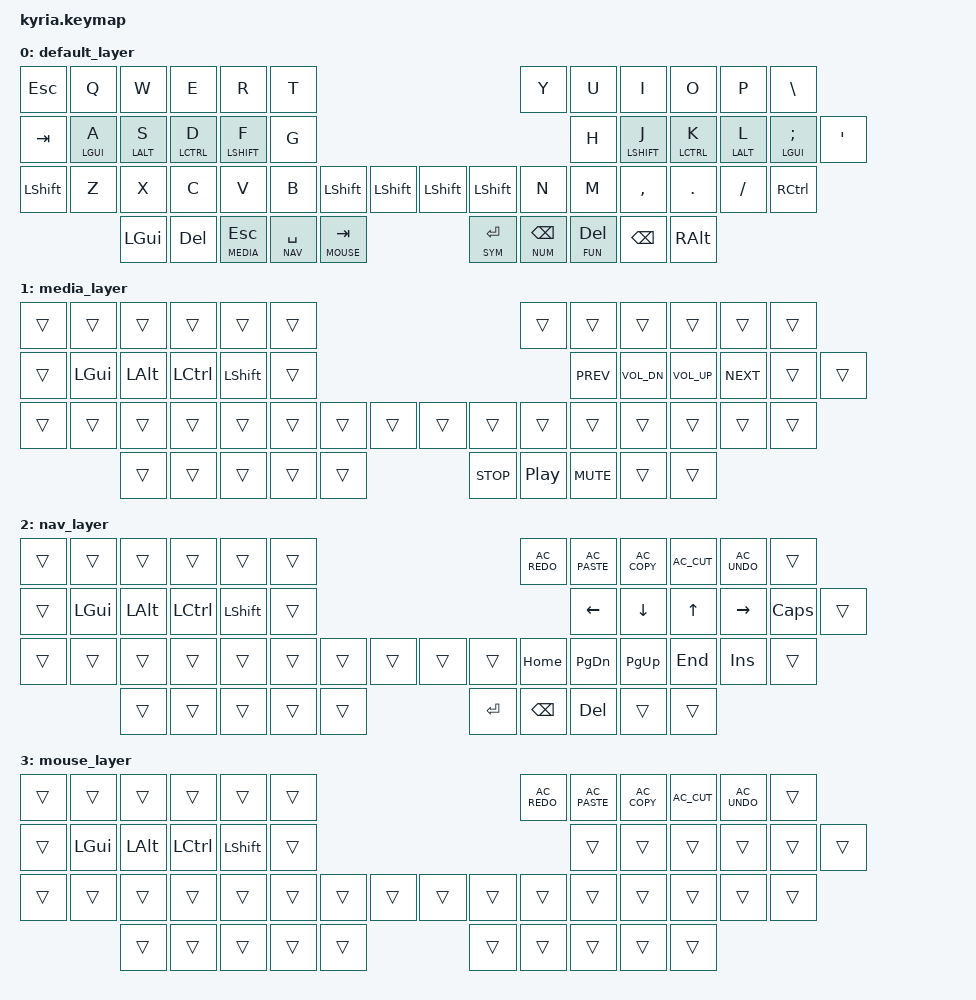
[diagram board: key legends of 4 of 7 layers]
/*
 * Copyright (c) 2020 The ZMK Contributors
 *
 * SPDX-License-Identifier: MIT
 *
 * This is an implementation of Miryoku for Kyria, with the following minor modifications:
 *   - Default is based on the default Kyria keymap.
 *   - This uses the QWERTY layout:
 *       MIRYOKU_ALPHAS=QWERTY
 *   - I am used to vi-style navigation:
 *       MIRYOKU_NAV=VI
 */

#include <behaviors.dtsi>
#include <dt-bindings/zmk/keys.h>
#include <dt-bindings/zmk/bt.h>

#define DEFAULT 0
#define MEDIA 1
#define NAV 2
#define MOUSE 3
#define SYM 4
#define NUM 5
#define FUN 6
#define BUTTON 7

/ {
	keymap {
		compatible = "zmk,keymap";

		default_layer {
// ---------------------------------------------------------------------------------------------------------------------------------
// |  ESC  |  Q  |  W  |  E   |  R   |  T   |                                          |  Y   |  U    |  I    |  O   |   P   |   \  |
// |  TAB  |  A  |  S  |  D   |  F   |  G   |                                          |  H   |  J    |  K    |  L   |   ;   |   '  |
// | SHIFT |  Z  |  X  |  C   |  V   |  B   | L SHIFT | L SHIFT |  | L SHIFT | L SHIFT |  N   |  M    |  ,    |  .   |   /   | CTRL |
//                     | GUI  | DEL  | RET  |  SPACE  |   ESC   |  |   RET   |  SPACE  | TAB  | BSPC  | R-ALT |
			bindings = <
	&kp ESC   &kp Q     &kp W     &kp E     &kp R     &kp T                                                &kp Y &kp U      &kp I         &kp O       &kp P        &kp BSLH
	&kp TAB   &lt LGUI A &lt LALT S &lt LCTRL D &lt LSHIFT F &kp G                                                &kp H &lt LSHIFT J  &lt LCTRL K     &lt LALT L   &lt LGUI SEMI &kp SQT
	&kp LSHFT &kp Z     &kp X     &kp C     &kp V     &kp B &kp LSHFT &kp LSHFT        &kp LSHFT &kp LSHFT &kp N &kp M      &kp COMMA     &kp DOT     &kp FSLH     &kp RCTRL
	                 &kp LGUI &kp DEL &lt MEDIA ESC &lt NAV SPACE &lt MOUSE TAB        &lt SYM RET   &lt NUM BSPC  &lt FUN DEL &kp BSPC &kp RALT
			>;

			sensor-bindings = <&inc_dec_kp C_VOL_UP C_VOL_DN &inc_dec_kp PG_UP PG_DN>;
		};

		media_layer {
		  bindings = <
	&trans &trans   &trans   &trans    &trans     &trans                                                        &trans     &trans       &trans       &trans     &trans &trans
	&trans &kp LGUI &kp LALT &kp LCTRL &kp LSHIFT &trans                                                        &kp C_PREV &kp C_VOL_DN &kp C_VOL_UP &kp C_NEXT &trans &trans
	&trans &trans   &trans   &trans    &trans     &trans &trans &trans              &trans     &trans           &trans     &trans       &trans       &trans     &trans &trans
	                         &trans    &trans     &trans &trans &trans              &kp C_STOP &kp C_PLAY_PAUSE &kp C_MUTE &trans       &trans
      >;
    };

    nav_layer {
		  bindings = <
	&trans &trans   &trans   &trans    &trans     &trans                                             &kp C_AC_REDO &kp C_AC_PASTE &kp C_AC_COPY &kp C_AC_CUT &kp C_AC_UNDO &trans
	&trans &kp LGUI &kp LALT &kp LCTRL &kp LSHIFT &trans                                             &kp LEFT      &kp DOWN       &kp UP        &kp RIGHT    &kp CAPS      &trans
	&trans &trans   &trans   &trans    &trans     &trans &trans &trans              &trans  &trans   &kp HOME      &kp PAGE_DOWN  &kp PAGE_UP   &kp END      &kp INSERT    &trans
	                         &trans    &trans     &trans &trans &trans              &kp RET &kp BSPC &kp DEL       &trans         &trans
      >;
    };

    mouse_layer { // WIP, no mouse keys yet available in mainstream ZMK
		  bindings = <
	&trans &trans   &trans   &trans    &trans     &trans                                            &kp C_AC_REDO &kp C_AC_PASTE &kp C_AC_COPY &kp C_AC_CUT &kp C_AC_UNDO &trans
	&trans &kp LGUI &kp LALT &kp LCTRL &kp LSHIFT &trans                                            &trans        &trans         &trans        &trans       &trans        &trans
	&trans &trans   &trans   &trans    &trans     &trans &trans &trans              &trans  &trans  &trans        &trans         &trans        &trans       &trans        &trans
	                         &trans    &trans     &trans &trans &trans              &trans  &trans  &trans        &trans         &trans
      >;
    };

    sym_layer {
		  bindings = <
	&trans &kp LBRC  &kp AMPS &kp STAR  &kp LPAR  &kp RBRC                                             &trans &trans     &trans    &trans   &trans   &trans
	&trans &kp COLON &kp DLLR &kp PRCNT &kp CARET &kp PLUS                                             &trans &kp LSHIFT &kp LCTRL &kp LALT &kp LGUI &trans
	&trans &kp TILDE &kp EXCL &kp AT    &kp HASH  &kp PIPE  &trans   &trans            &trans  &trans  &trans &trans     &trans    &trans   &trans   &trans
	                          &trans    &trans    &kp LPAR  &kp RPAR &kp UNDER         &trans  &trans  &trans &trans     &trans    &trans
      >;
    };

    num_layer {
		  bindings = <
	&trans &kp LBKT  &kp N7   &kp N8   &kp N9   &kp RBKT                                             &trans &trans     &trans    &trans   &trans   &trans
	&trans &kp SEMI  &kp N4   &kp N5   &kp N6   &kp EQUAL                                            &trans &kp LSHIFT &kp LCTRL &kp LALT &kp LGUI &trans
	&trans &kp GRAVE &kp N1   &kp N2   &kp N3   &kp BSLH  &trans &trans              &trans  &trans  &trans &trans     &trans    &trans   &trans   &trans
	                          &trans   &trans   &kp DOT   &kp N0 &kp MINUS           &trans  &trans  &trans &trans     &trans    &trans
      >;
    };

    fun_layer {
		  bindings = <
	&trans &kp F12   &kp F7   &kp F8   &kp F9   &kp PRINTSCREEN                                                 &trans &trans     &trans    &trans   &trans   &trans
	&trans &kp F11   &kp F4   &kp F5   &kp F6   &kp SCROLLLOCK                                                  &trans &kp LSHIFT &kp LCTRL &kp LALT &kp LGUI &trans
	&trans &kp F10   &kp F1   &kp F2   &kp F3   &kp PAUSE_BREAK      &trans    &trans           &trans  &trans  &trans &trans     &trans    &trans   &trans   &trans
	                          &trans   &trans   &kp K_CONTEXT_MENU   &kp SPACE &kp TAB          &trans  &trans  &trans &trans     &trans    &trans
      >;
    };
	};
};
